VERSION ""

NS_ :

BS_:

BU_: VehicleECU EngineECU TransmissionECU BrakingECU

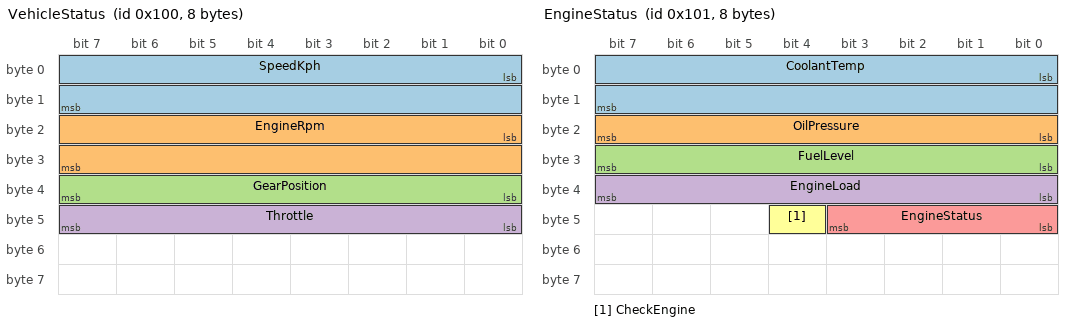
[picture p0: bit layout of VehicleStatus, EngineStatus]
BO_ 256 VehicleStatus: 8 VehicleECU
 SG_ SpeedKph : 0|16@1+ (0.01,0) [0|300] "km/h" EngineECU,TransmissionECU
 SG_ EngineRpm : 16|16@1+ (0.25,0) [0|8000] "rpm" EngineECU
 SG_ GearPosition : 32|8@1+ (1,0) [0|6] "" TransmissionECU
 SG_ Throttle : 40|8@1+ (0.5,0) [0|100] "%" EngineECU

BO_ 257 EngineStatus: 8 EngineECU
 SG_ CoolantTemp : 0|16@1- (0.1,-40) [-40|215] "C" VehicleECU
 SG_ OilPressure : 16|8@1+ (0.1,0) [0|10] "bar" VehicleECU
 SG_ FuelLevel : 24|8@1+ (0.5,0) [0|100] "%" VehicleECU
 SG_ EngineLoad : 32|8@1+ (0.4,0) [0|100] "%" VehicleECU
 SG_ EngineStatus : 40|4@1+ (1,0) [0|15] "" VehicleECU
 SG_ CheckEngine : 44|1@1+ (1,0) [0|1] "" VehicleECU

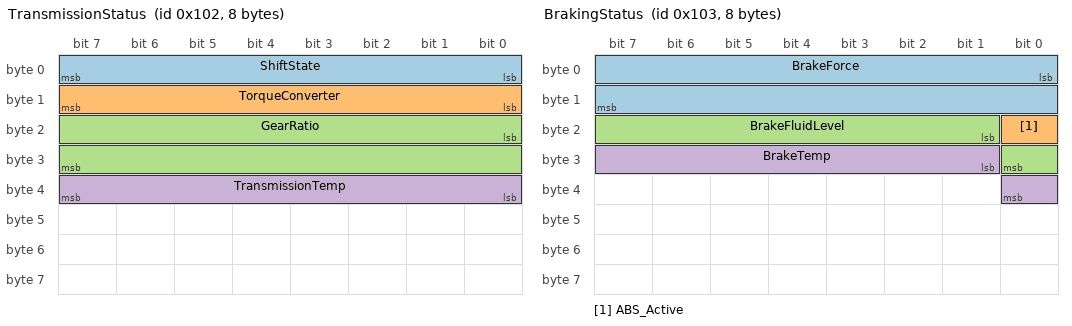
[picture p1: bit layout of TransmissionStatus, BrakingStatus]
BO_ 258 TransmissionStatus: 8 TransmissionECU
 SG_ ShiftState : 0|8@1+ (1,0) [0|6] "" VehicleECU
 SG_ TorqueConverter : 8|8@1+ (0.5,0) [0|100] "%" VehicleECU
 SG_ GearRatio : 16|16@1+ (0.001,0) [1|10] "" VehicleECU
 SG_ TransmissionTemp : 32|8@1- (1,-40) [-40|215] "C" VehicleECU

BO_ 259 BrakingStatus: 8 BrakingECU
 SG_ BrakeForce : 0|16@1+ (0.1,0) [0|10000] "N" VehicleECU
 SG_ ABS_Active : 16|1@1+ (1,0) [0|1] "" VehicleECU
 SG_ BrakeFluidLevel : 17|8@1+ (0.5,0) [0|100] "%" VehicleECU
 SG_ BrakeTemp : 25|8@1- (1,-40) [-40|200] "C" VehicleECU

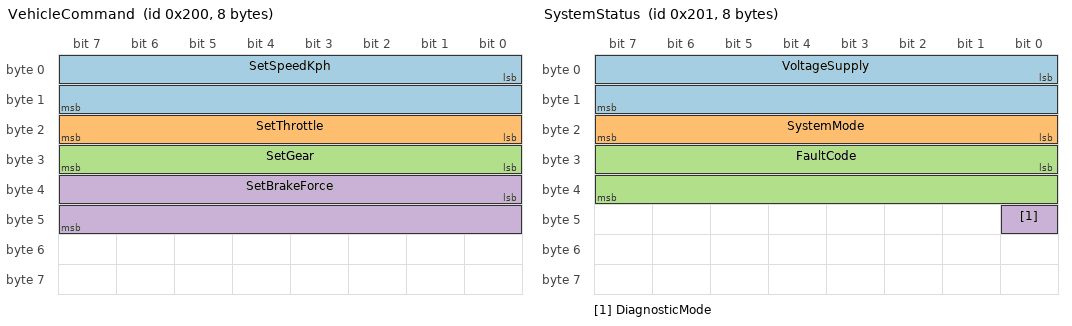
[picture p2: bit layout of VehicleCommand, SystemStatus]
BO_ 512 VehicleCommand: 8 VehicleECU
 SG_ SetSpeedKph : 0|16@1+ (0.01,0) [0|300] "km/h" EngineECU
 SG_ SetThrottle : 16|8@1+ (0.5,0) [0|100] "%" EngineECU
 SG_ SetGear : 24|8@1+ (1,0) [0|6] "" TransmissionECU
 SG_ SetBrakeForce : 32|16@1+ (0.1,0) [0|10000] "N" BrakingECU

BO_ 513 SystemStatus: 8 VehicleECU
 SG_ VoltageSupply : 0|16@1+ (0.01,8) [8|16] "V" EngineECU,TransmissionECU,BrakingECU
 SG_ SystemMode : 16|8@1+ (1,0) [0|3] "" EngineECU
 SG_ FaultCode : 24|16@1+ (1,0) [0|65535] "" EngineECU
 SG_ DiagnosticMode : 40|1@1+ (1,0) [0|1] "" EngineECU

VAL_ 258 ShiftState 0 "Park" 1 "Reverse" 2 "Neutral" 3 "Drive" 4 "Sport" 5 "Low" 6 "Manual" ;
VAL_ 257 EngineStatus 0 "Off" 1 "Starting" 2 "Running" 3 "Idle" 4 "Accelerating" 5 "Decelerating" 6 "Fault" ;
VAL_ 259 ABS_Active 0 "Inactive" 1 "Active" ;
VAL_ 513 SystemMode 0 "Idle" 1 "Normal" 2 "Sport" 3 "ECO" ;
VAL_ 513 DiagnosticMode 0 "Normal" 1 "Diagnostic" ;

BA_DEF_ BO_ "GenMsgCycleTime" INT 0 10000;
BA_DEF_ SG_ "GenSigSendType" ENUM "Cyclic","OnWrite","OnWriteWithRepetition","OnChange","OnChangeWithRepetition";
BA_DEF_DEF_ "GenMsgCycleTime" 100;
BA_DEF_DEF_ "GenSigSendType" "Cyclic";

BA_ "GenMsgCycleTime" BO_ 256 50;
BA_ "GenMsgCycleTime" BO_ 258 50;
BA_ "GenMsgCycleTime" BO_ 259 50;
BA_ "GenMsgCycleTime" BO_ 512 0;
BA_ "GenMsgCycleTime" BO_ 513 1000;

CM_ BO_ 256 "Vehicle speed and engine status information";
CM_ BO_ 257 "Engine parameters and diagnostics";
CM_ BO_ 258 "Transmission status and gear information";
CM_ BO_ 259 "Braking system status";
CM_ BO_ 512 "Commands sent to vehicle subsystems";
CM_ BO_ 513 "System health and diagnostic status";
CM_ SG_ 256 SpeedKph "Current vehicle speed";
CM_ SG_ 256 EngineRpm "Engine rotations per minute";
CM_ SG_ 257 CoolantTemp "Engine coolant temperature";
CM_ SG_ 257 FuelLevel "Fuel tank level percentage";
CM_ SG_ 259 BrakeForce "Total brake force applied";
CM_ SG_ 259 ABS_Active "Anti-lock braking system status";
